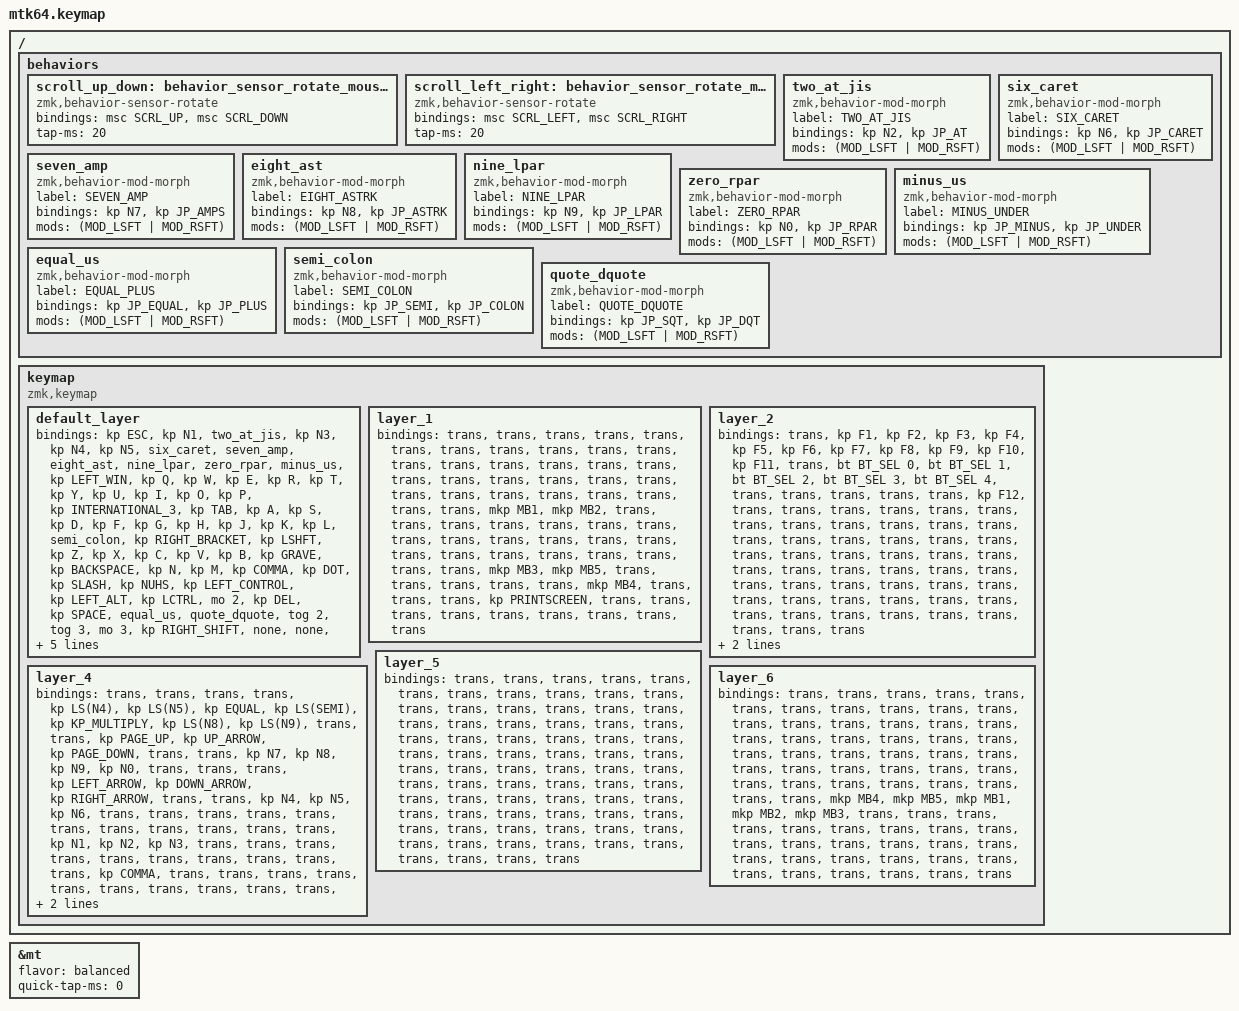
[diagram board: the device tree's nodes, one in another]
#include <behaviors.dtsi>
#include <dt-bindings/zmk/bt.h>
#include <dt-bindings/zmk/keys.h>
#include <dt-bindings/zmk/pointing.h>
#include "keycode_japanese.h"

// スクロール量の設定

#define ZMK_POINTING_DEFAULT_SCRL_VAL 100

&mt {
    flavor = "balanced";
    quick-tap-ms = <0>;
};

/ {
    behaviors {
        // 垂直スクロール用のbehaviorの設定

        scroll_up_down: behavior_sensor_rotate_mouse_wheel_up_down {
            compatible = "zmk,behavior-sensor-rotate";
            #sensor-binding-cells = <0>;
            bindings = <&msc SCRL_UP>, <&msc SCRL_DOWN>;

            tap-ms = <20>; // スクロールのタップ時間
        };

        // 水平スクロール用のbehaviorの設定

        scroll_left_right: behavior_sensor_rotate_mouse_wheel_left_right {
            compatible = "zmk,behavior-sensor-rotate";
            #sensor-binding-cells = <0>;
            bindings = <&msc SCRL_LEFT>, <&msc SCRL_RIGHT>;

            tap-ms = <20>; // スクロールのタップ時間
        };

        // --- ここから追加：2 / @（Shift+2）をJIS環境で正しく出す ---

        two_at_jis: two_at_jis {
            compatible = "zmk,behavior-mod-morph";
            label = "TWO_AT_JIS";
            #binding-cells = <0>;

            // 単押し → "2"、Shift併用 → "@"
            // "@": JISでは JP_AT（= LBKT）を送るのが正解

            bindings = <&kp N2>, <&kp JP_AT>;

            // 左右どちらかのShiftが押されていたら後者（@）を発火

            mods = <(MOD_LSFT | MOD_RSFT)>;

            // keep-modsは未指定（=0）。余計なShiftは送らない＝JISで安定
        };

        // --- 追加ここまで ---
        // --- 数字段（US感覚でのShift記号） ---

        six_caret: six_caret {
            compatible = "zmk,behavior-mod-morph";
            label = "SIX_CARET";
            #binding-cells = <0>;
            bindings = <&kp N6>, <&kp JP_CARET>;

            // 6 / ^

            mods = <(MOD_LSFT | MOD_RSFT)>;
        };

        seven_amp: seven_amp {
            compatible = "zmk,behavior-mod-morph";
            label = "SEVEN_AMP";
            #binding-cells = <0>;
            bindings = <&kp N7>, <&kp JP_AMPS>;

            // 7 / &

            mods = <(MOD_LSFT | MOD_RSFT)>;
        };

        eight_ast: eight_ast {
            compatible = "zmk,behavior-mod-morph";
            label = "EIGHT_ASTRK";
            #binding-cells = <0>;
            bindings = <&kp N8>, <&kp JP_ASTRK>;

            // 8 / *

            mods = <(MOD_LSFT | MOD_RSFT)>;
        };

        nine_lpar: nine_lpar {
            compatible = "zmk,behavior-mod-morph";
            label = "NINE_LPAR";
            #binding-cells = <0>;
            bindings = <&kp N9>, <&kp JP_LPAR>;

            // 9 / (

            mods = <(MOD_LSFT | MOD_RSFT)>;
        };

        zero_rpar: zero_rpar {
            compatible = "zmk,behavior-mod-morph";
            label = "ZERO_RPAR";
            #binding-cells = <0>;
            bindings = <&kp N0>, <&kp JP_RPAR>;

            // 0 / )

            mods = <(MOD_LSFT | MOD_RSFT)>;
        };

        // --- 記号ペア（US感覚でのShift記号） ---

        minus_us: minus_us {
            compatible = "zmk,behavior-mod-morph";
            label = "MINUS_UNDER";
            #binding-cells = <0>;
            bindings = <&kp JP_MINUS>, <&kp JP_UNDER>;

            // - / _

            mods = <(MOD_LSFT | MOD_RSFT)>;
        };

        equal_us: equal_us {
            compatible = "zmk,behavior-mod-morph";
            label = "EQUAL_PLUS";
            #binding-cells = <0>;
            bindings = <&kp JP_EQUAL>, <&kp JP_PLUS>;

            // = / +

            mods = <(MOD_LSFT | MOD_RSFT)>;
        };

        semi_colon: semi_colon {
            compatible = "zmk,behavior-mod-morph";
            label = "SEMI_COLON";
            #binding-cells = <0>;
            bindings = <&kp JP_SEMI>, <&kp JP_COLON>;

            // ; / :

            mods = <(MOD_LSFT | MOD_RSFT)>;
        };

        quote_dquote: quote_dquote {
            compatible = "zmk,behavior-mod-morph";
            label = "QUOTE_DQUOTE";
            #binding-cells = <0>;
            bindings = <&kp JP_SQT>, <&kp JP_DQT>;

            // ' / "

            mods = <(MOD_LSFT | MOD_RSFT)>;
        };
    };
};

/ {
    keymap {
        compatible = "zmk,keymap";

        default_layer {
            bindings = <
&kp ESC  &kp N1  &two_at_jis  &kp N3  &kp N4  &kp N5  &six_caret  &seven_amp  &eight_ast  &nine_lpar  &zero_rpar  &minus_us  &kp LEFT_WIN  &kp Q  &kp W  &kp E  &kp R  &kp T  &kp Y  &kp U  &kp I  &kp O  &kp P  &kp INTERNATIONAL_3  &kp TAB  &kp A  &kp S  &kp D  &kp F  &kp G  &kp H  &kp J  &kp K  &kp L  &semi_colon  &kp RIGHT_BRACKET  &kp LSHFT  &kp Z  &kp X  &kp C  &kp V  &kp B  &kp GRAVE  &kp BACKSPACE  &kp N  &kp M  &kp COMMA  &kp DOT  &kp SLASH  &kp NUHS  &kp LEFT_CONTROL  &kp LEFT_ALT  &kp LCTRL  &mo 2  &kp DEL  &kp SPACE  &equal_us  &quote_dquote  &tog 2  &tog 3  &mo 3  &kp RIGHT_SHIFT  &none  &none  &mo 1  &kp RETURN  &mo 1  &mo 2  &mo 4  &mo 1  &mo 2  &mo 4  &mo 1  &mo 2  &mo 4
            >;

            sensor-bindings =
                <&inc_dec_kp LEFT_ARROW RIGHT_ARROW>,
                <&scroll_up_down>;
        };

        layer_1 {
            bindings = <
&trans  &trans  &trans  &trans  &trans  &trans  &trans  &trans  &trans  &trans  &trans  &trans  &trans  &trans  &trans  &trans  &trans  &trans  &trans  &trans  &trans  &trans  &trans  &trans  &trans  &trans  &trans  &trans  &trans  &trans  &trans  &mkp MB1  &mkp MB2  &trans  &trans  &trans  &trans  &trans  &trans  &trans  &trans  &trans  &trans  &trans  &trans  &trans  &trans  &trans  &trans  &trans  &trans  &trans  &trans  &trans  &mkp MB3  &mkp MB5  &trans  &trans  &trans  &trans  &trans  &mkp MB4  &trans  &trans  &trans  &kp PRINTSCREEN  &trans  &trans  &trans  &trans  &trans  &trans  &trans  &trans  &trans
            >;
        };

        layer_2 {
            bindings = <
&trans  &kp F1  &kp F2  &kp F3  &kp F4  &kp F5  &kp F6  &kp F7  &kp F8  &kp F9  &kp F10  &kp F11  &trans  &bt BT_SEL 0  &bt BT_SEL 1  &bt BT_SEL 2  &bt BT_SEL 3  &bt BT_SEL 4  &trans  &trans  &trans  &trans  &trans  &kp F12  &trans  &trans  &trans  &trans  &trans  &trans  &trans  &trans  &trans  &trans  &trans  &trans  &trans  &trans  &trans  &trans  &trans  &trans  &trans  &trans  &trans  &trans  &trans  &trans  &trans  &trans  &trans  &trans  &trans  &trans  &trans  &trans  &trans  &trans  &trans  &trans  &trans  &trans  &trans  &trans  &trans  &trans  &trans  &trans  &trans  &trans  &trans  &trans  &trans  &trans  &trans
            >;

            sensor-bindings = <
                &inc_dec_kp TAB LC(TAB) 
                &inc_dec_kp PG_UP PG_DN
            >;
        };

        layer_4 {
            bindings = <
&trans  &trans  &trans  &trans  &kp LS(N4)  &kp LS(N5)  &kp EQUAL  &kp LS(SEMI)  &kp KP_MULTIPLY  &kp LS(N8)  &kp LS(N9)  &trans  &trans  &kp PAGE_UP  &kp UP_ARROW  &kp PAGE_DOWN  &trans  &trans  &kp N7  &kp N8  &kp N9  &kp N0  &trans  &trans  &trans  &kp LEFT_ARROW  &kp DOWN_ARROW  &kp RIGHT_ARROW  &trans  &trans  &kp N4  &kp N5  &kp N6  &trans  &trans  &trans  &trans  &trans  &trans  &trans  &trans  &trans  &trans  &trans  &kp N1  &kp N2  &kp N3  &trans  &trans  &trans  &trans  &trans  &trans  &trans  &trans  &trans  &trans  &kp COMMA  &trans  &trans  &trans  &trans  &trans  &trans  &trans  &trans  &trans  &trans  &trans  &trans  &trans  &trans  &trans  &trans  &trans
            >;
        };

        layer_5 {
            bindings = <
&trans  &trans  &trans  &trans  &trans  &trans  &trans  &trans  &trans  &trans  &trans  &trans  &trans  &trans  &trans  &trans  &trans  &trans  &trans  &trans  &trans  &trans  &trans  &trans  &trans  &trans  &trans  &trans  &trans  &trans  &trans  &trans  &trans  &trans  &trans  &trans  &trans  &trans  &trans  &trans  &trans  &trans  &trans  &trans  &trans  &trans  &trans  &trans  &trans  &trans  &trans  &trans  &trans  &trans  &trans  &trans  &trans  &trans  &trans  &trans  &trans  &trans  &trans  &trans  &trans  &trans  &trans  &trans  &trans  &trans  &trans  &trans  &trans  &trans  &trans
            >;
        };

        layer_6 {
            bindings = <
&trans  &trans  &trans  &trans  &trans  &trans  &trans  &trans  &trans  &trans  &trans  &trans  &trans  &trans  &trans  &trans  &trans  &trans  &trans  &trans  &trans  &trans  &trans  &trans  &trans  &trans  &trans  &trans  &trans  &trans  &trans  &trans  &trans  &trans  &trans  &trans  &trans  &trans  &trans  &trans  &trans  &trans  &trans  &mkp MB4  &mkp MB5  &mkp MB1  &mkp MB2  &mkp MB3  &trans  &trans  &trans  &trans  &trans  &trans  &trans  &trans  &trans  &trans  &trans  &trans  &trans  &trans  &trans  &trans  &trans  &trans  &trans  &trans  &trans  &trans  &trans  &trans  &trans  &trans  &trans
            >;
        };
    };
};
